# STM32H7A3xx register map
File version: 1.0
Registers are 32-bit, access not given, reset 0x0 unless marked. A register's access mark holds for its fields unless they carry their own. Offsets are from the block's base; [hi:lo] are bit positions; {n}, {i} and the like mark numbered series.

## HSEM_COMMON
Base 0x48020900
0x00 IER
0x04 ICR
0x08 ISR
0x0C MISR

## RNG
Base 0x48021800
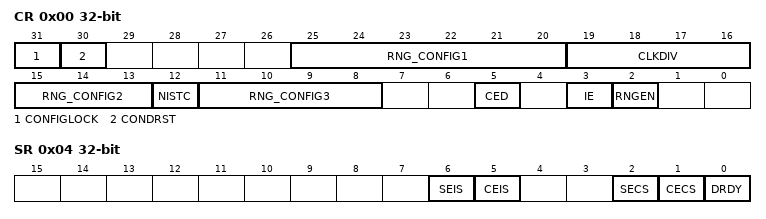
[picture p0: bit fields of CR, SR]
0x00 CR
  [31] CONFIGLOCK, [30] CONDRST, [25:20] RNG_CONFIG1, [19:16] CLKDIV, [15:13] RNG_CONFIG2, [12] NISTC, [11:8] RNG_CONFIG3, [5] CED, [3] IE, [2] RNGEN
0x04 SR
  [6] SEIS, [5] CEIS, [2] SECS, [1] CECS, [0] DRDY
0x08 DR
0x10 HTCR

## SDMMC2
Base 0x48022400
Same registers: SDMMC1 0x52007000
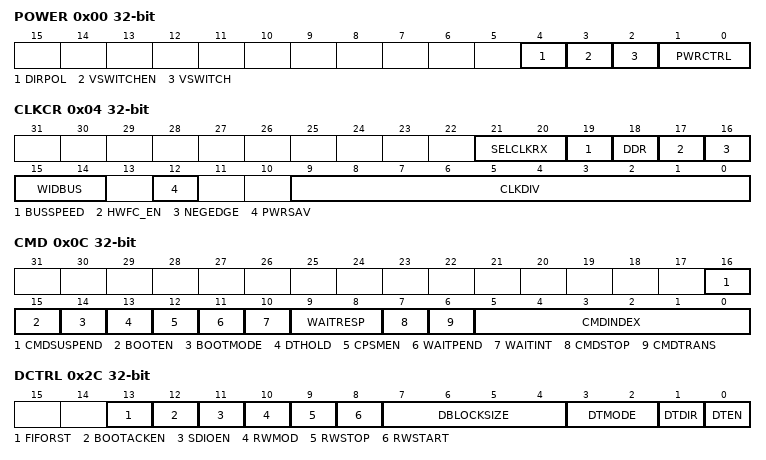
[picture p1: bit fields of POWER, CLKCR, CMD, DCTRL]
0x00 POWER
  [4] DIRPOL, [3] VSWITCHEN, [2] VSWITCH, [1:0] PWRCTRL
0x04 CLKCR
  [21:20] SELCLKRX, [19] BUSSPEED, [18] DDR, [17] HWFC_EN, [16] NEGEDGE, [15:14] WIDBUS, [12] PWRSAV, [9:0] CLKDIV
0x08 ARG
  [31:0] CMDARG
0x0C CMD
  [16] CMDSUSPEND, [15] BOOTEN, [14] BOOTMODE, [13] DTHOLD, [12] CPSMEN, [11] WAITPEND, [10] WAITINT, [9:8] WAITRESP, [7] CMDSTOP, [6] CMDTRANS, [5:0] CMDINDEX
0x10 RESPCMD
  [5:0] RESPCMD
{0x10+4i} RESP{i} (i=1..4)
  [31:0] CARDSTATUS{i}
0x24 DTIMER
  [31:0] DATATIME
0x28 DLEN
  [24:0] DATALENGTH
0x2C DCTRL
  [13] FIFORST, [12] BOOTACKEN, [11] SDIOEN, [10] RWMOD, [9] RWSTOP, [8] RWSTART, [7:4] DBLOCKSIZE, [3:2] DTMODE, [1] DTDIR, [0] DTEN
0x30 DCOUNT
  [24:0] DATACOUNT
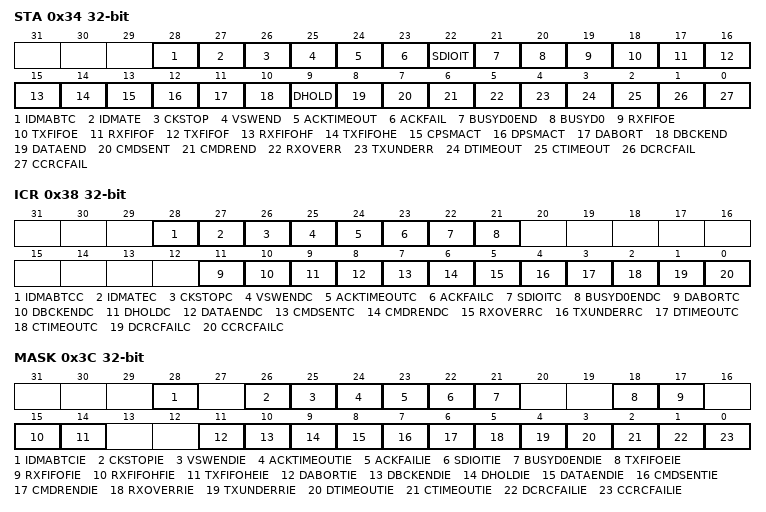
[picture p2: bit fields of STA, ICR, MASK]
0x34 STA
  [28] IDMABTC, [27] IDMATE, [26] CKSTOP, [25] VSWEND, [24] ACKTIMEOUT, [23] ACKFAIL, [22] SDIOIT, [21] BUSYD0END, [20] BUSYD0, [19] RXFIFOE, [18] TXFIFOE, [17] RXFIFOF, [16] TXFIFOF, [15] RXFIFOHF, [14] TXFIFOHE, [13] CPSMACT, [12] DPSMACT, [11] DABORT, [10] DBCKEND, [9] DHOLD, [8] DATAEND, [7] CMDSENT, [6] CMDREND, [5] RXOVERR, [4] TXUNDERR, [3] DTIMEOUT, [2] CTIMEOUT, [1] DCRCFAIL, [0] CCRCFAIL
0x38 ICR
  [28] IDMABTCC, [27] IDMATEC, [26] CKSTOPC, [25] VSWENDC, [24] ACKTIMEOUTC, [23] ACKFAILC, [22] SDIOITC, [21] BUSYD0ENDC, [11] DABORTC, [10] DBCKENDC, [9] DHOLDC, [8] DATAENDC, [7] CMDSENTC, [6] CMDRENDC, [5] RXOVERRC, [4] TXUNDERRC, [3] DTIMEOUTC, [2] CTIMEOUTC, [1] DCRCFAILC, [0] CCRCFAILC
0x3C MASK
  [28] IDMABTCIE, [26] CKSTOPIE, [25] VSWENDIE, [24] ACKTIMEOUTIE, [23] ACKFAILIE, [22] SDIOITIE, [21] BUSYD0ENDIE, [18] TXFIFOEIE, [17] RXFIFOFIE, [15] RXFIFOHFIE, [14] TXFIFOHEIE, [11] DABORTIE, [10] DBCKENDIE, [9] DHOLDIE, [8] DATAENDIE, [7] CMDSENTIE, [6] CMDRENDIE, [5] RXOVERRIE, [4] TXUNDERRIE, [3] DTIMEOUTIE, [2] CTIMEOUTIE, [1] DCRCFAILIE, [0] CCRCFAILIE
0x40 ACKTIME
  [24:0] ACKTIME
0x50 IDMACTRL
0x54 IDMABSIZE
  [12:5] IDMABNDT
0x58 IDMABASE0
0x5C IDMABASE1
0x80 FIFO
  [31:0] FIFODATA
0x3FC IPVR

## DLYB_SDMMC2
Base 0x48022800
Same registers: DLYB_OCTOSPI1 0x52006000, DLYB_SDMMC1 0x52008000, DLYB_OCTOSPI2 0x5200B000
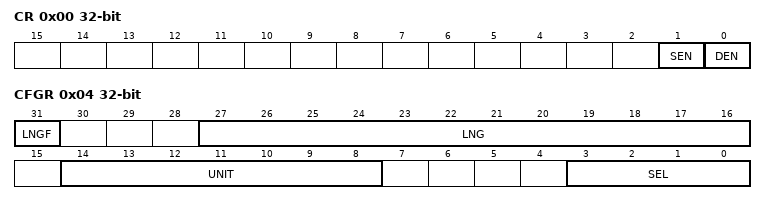
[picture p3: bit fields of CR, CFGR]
0x00 CR
  [1] SEN, [0] DEN
0x04 CFGR
  [31] LNGF, [27:16] LNG, [14:8] UNIT, [3:0] SEL

## BDMA1
Base 0x48022C00
Same registers: BDMA2 0x58025400
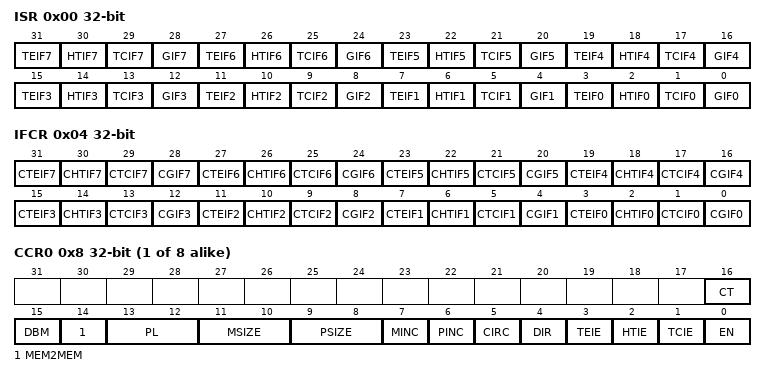
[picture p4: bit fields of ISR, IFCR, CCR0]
0x00 ISR
  [4n+3] TEIF{n} (n=0..7), [4n+2] HTIF{n} (n=0..7), [4n+1] TCIF{n} (n=0..7), [4n] GIF{n} (n=0..7)
0x04 IFCR
  [4n+3] CTEIF{n} (n=0..7), [4n+2] CHTIF{n} (n=0..7), [4n+1] CTCIF{n} (n=0..7), [4n] CGIF{n} (n=0..7)
{0x8+0x14*i} CCR{i} (i=0..7)
  [16] CT, [15] DBM, [14] MEM2MEM, [13:12] PL, [11:10] MSIZE, [9:8] PSIZE, [7] MINC, [6] PINC, [5] CIRC, [4] DIR, [3] TEIE, [2] HTIE, [1] TCIE, [0] EN
{0xC+0x14*i} CNDTR{i} (i=0..7)
  [15:0] NDT
{0x14+0x14*i} CPAR{i} (i=0..7)
  [31:0] PA
{0x20+0x14*i} CM0AR{i} (i=0..7)
  [31:0] MA
{0x30+0x14*i} CM1AR{i} (i=0..7)
  [31:0] MA

## LTDC
Base 0x50001000
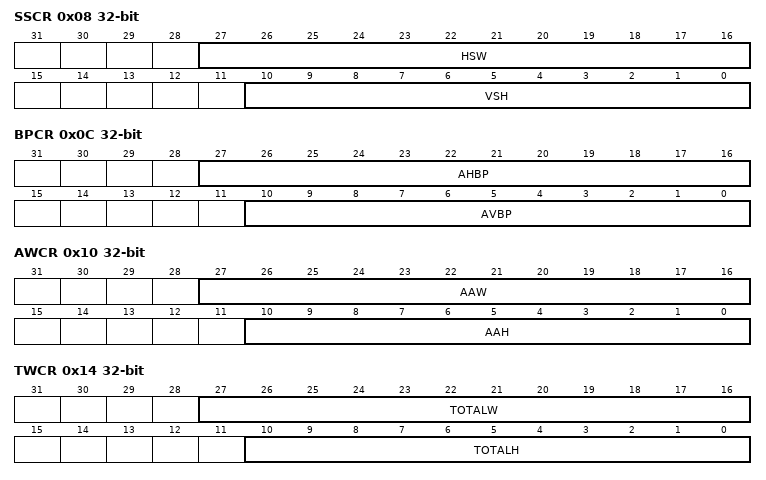
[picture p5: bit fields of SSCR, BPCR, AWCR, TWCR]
0x08 SSCR
  [27:16] HSW, [10:0] VSH
0x0C BPCR
  [27:16] AHBP, [10:0] AVBP
0x10 AWCR
  [27:16] AAW, [10:0] AAH
0x14 TWCR
  [27:16] TOTALW, [10:0] TOTALH
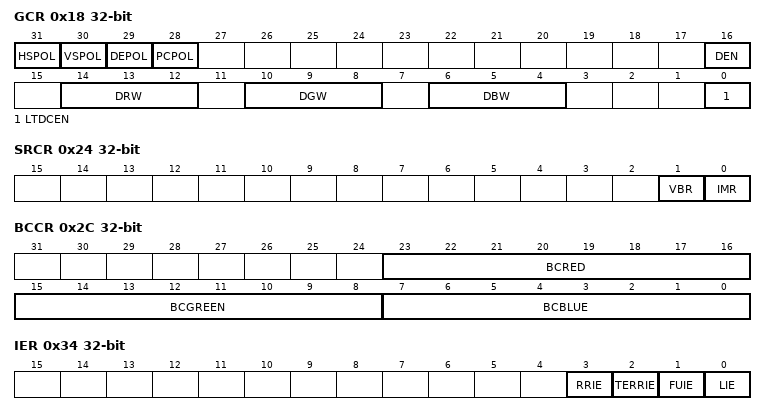
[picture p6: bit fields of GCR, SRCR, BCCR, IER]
0x18 GCR
  [31] HSPOL, [30] VSPOL, [29] DEPOL, [28] PCPOL, [16] DEN, [14:12] DRW, [10:8] DGW, [6:4] DBW, [0] LTDCEN
0x24 SRCR
  [1] VBR, [0] IMR
0x2C BCCR
  [23:16] BCRED, [15:8] BCGREEN, [7:0] BCBLUE
0x34 IER
  [3] RRIE, [2] TERRIE, [1] FUIE, [0] LIE
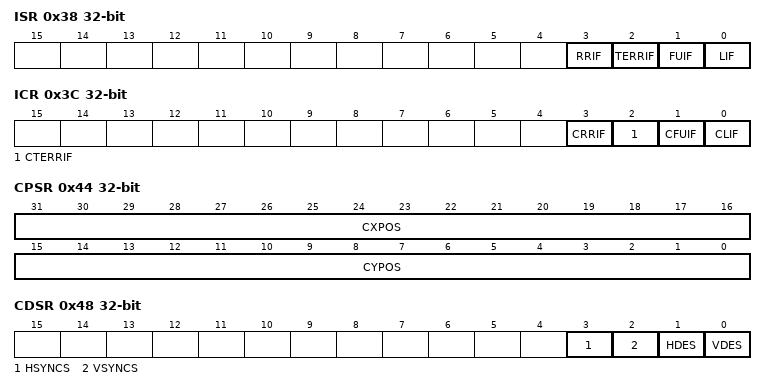
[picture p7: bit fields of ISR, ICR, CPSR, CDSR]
0x38 ISR
  [3] RRIF, [2] TERRIF, [1] FUIF, [0] LIF
0x3C ICR
  [3] CRRIF, [2] CTERRIF, [1] CFUIF, [0] CLIF
0x40 LIPCR
  [10:0] LIPOS
0x44 CPSR
  [31:16] CXPOS, [15:0] CYPOS
0x48 CDSR
  [3] HSYNCS, [2] VSYNCS, [1] HDES, [0] VDES
0x84 CR1
0x88 WHPCR1
0x90 WVPCR1
0x9C CKCR1
0xAC PFCR1
0xC0 CACR1
0xD8 DCCR1
0xF4 BFCR1
0x104 CR2
0x108 WHPCR2
0x110 WVPCR2
0x11C CFBAR1
0x11C CKCR2
0x12C PFCR2
0x140 CACR2
0x148 CFBLR1
0x158 DCCR2
0x174 BFCR2
0x178 CFBLNR1
0x19C CFBAR2
0x1B8 CLUTWR1
0x1C8 CFBLR2
0x1F8 CFBLNR2
0x238 CLUTWR2
